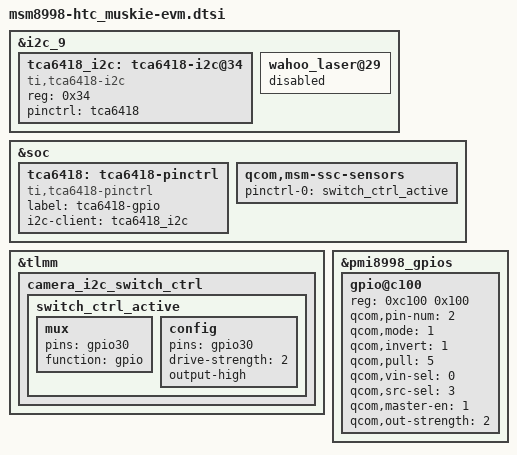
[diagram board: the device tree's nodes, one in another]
/* Copyright (c) 2016, The Linux Foundation. All rights reserved.
 *
 * This program is free software; you can redistribute it and/or modify
 * it under the terms of the GNU General Public License version 2 and
 * only version 2 as published by the Free Software Foundation.
 *
 * This program is distributed in the hope that it will be useful,
 * but WITHOUT ANY WARRANTY; without even the implied warranty of
 * MERCHANTABILITY or FITNESS FOR A PARTICULAR PURPOSE.  See the
 * GNU General Public License for more details.
 */


#include "base-msm8998-mtp.dtsi"
#include "msm8998-htc_muskie.dtsi"
#include "msm8998-camera-sensor.dtsi"
#include "msm8998-audio-evm.dtsi"
#include "msm8998-htc-fingerprint-muskie-evm.dtsi"
#include "msm8998-touch-muskie-xa.dtsi"

&i2c_9 {
	tca6418_i2c: tca6418-i2c@34 {
		compatible = "ti,tca6418-i2c";
		reg = <0x34>;
		pinctrl = <&tca6418>;
	};
};

&soc {
	tca6418: tca6418-pinctrl {
		compatible = "ti,tca6418-pinctrl";
		#gpio-cells = <2>;
		label = "tca6418-gpio";
		i2c-client = <&tca6418_i2c>;
	 };

	qcom,msm-ssc-sensors {
		pinctrl-names = "default";
		pinctrl-0 = <&switch_ctrl_active>;
	};
};

&tlmm {
	camera_i2c_switch_ctrl {
		switch_ctrl_active: switch_ctrl_active {
			mux {
				pins = "gpio30";
				function = "gpio";
			};

			config {
				pins = "gpio30";
				drive-strength = <2>;
				output-high;
			};
		};
	};
};

&pmi8998_gpios {
	gpio@c100 {
		reg = <0xc100 0x100>;
		qcom,pin-num = <2>;
		status = "okay";
		qcom,mode = <1>; // Digital output
		qcom,invert = <1>;
		qcom,pull = <5>; // No Pull
		qcom,vin-sel = <0>; // 1.8 V, VIN0
		qcom,src-sel = <3>;
		qcom,master-en = <1>; // enable GPIO
		qcom,out-strength = <2>; // Output strength medium
	};
};

&i2c_9 {
	wahoo_laser@29 {
		status = "disabled";
	};
};

#include "msm8998-htc-usb-evm.dtsi"
